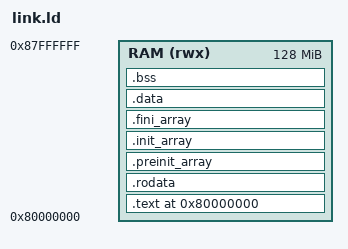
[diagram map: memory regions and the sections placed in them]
OUTPUT_ARCH("riscv")
ENTRY(_start)

MEMORY
{
    RAM (rwx) : ORIGIN = 0x80000000, LENGTH = 128M
}

SECTIONS
{
    . = ORIGIN(RAM);

    .text :
    {
        KEEP(*(.text.init))
        *(.text .text.*)
    } > RAM

    .rodata :
    {
        *(.rodata .rodata.*)
        *(.srodata .srodata.*)
    } > RAM

    . = ALIGN(8);
    .preinit_array :
    {
        PROVIDE(__preinit_array_start = .);
        KEEP(*(.preinit_array))
        PROVIDE(__preinit_array_end = .);
    } > RAM

    .init_array :
    {
        PROVIDE(__init_array_start = .);
        KEEP(*(SORT(.init_array.*)))
        KEEP(*(.init_array))
        PROVIDE(__init_array_end = .);
    } > RAM

    .fini_array :
    {
        PROVIDE(__fini_array_start = .);
        KEEP(*(SORT(.fini_array.*)))
        KEEP(*(.fini_array))
        PROVIDE(__fini_array_end = .);
    } > RAM

    .data :
    {
        *(.data .data.*)
        *(.sdata .sdata.*)
    } > RAM

    . = ALIGN(8);
    .bss (NOLOAD) :
    {
        PROVIDE(__bss_start = .);
        *(.sbss .sbss.*)
        *(.bss .bss.*)
        *(COMMON)
        . = ALIGN(8);
        PROVIDE(__bss_end = .);
    } > RAM

    . = ALIGN(8);
    PROVIDE(_end = .);
    PROVIDE(__heap_start = .);

    PROVIDE(__stack_top = ORIGIN(RAM) + LENGTH(RAM));
}
